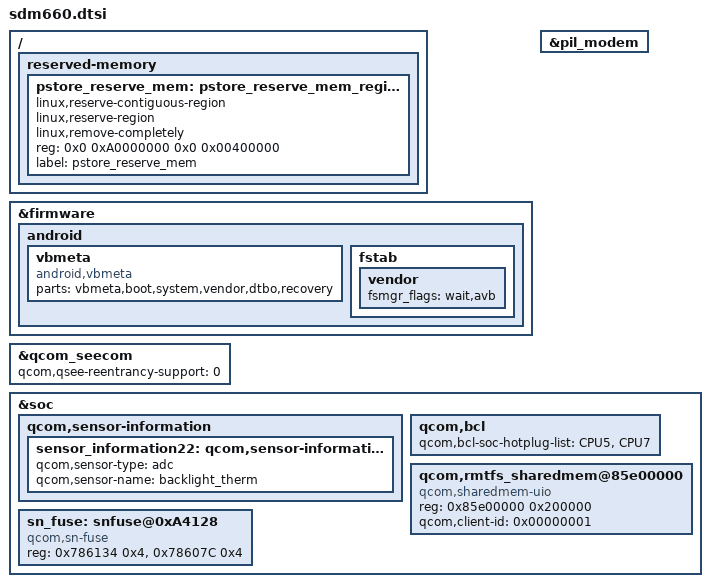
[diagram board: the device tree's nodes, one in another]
/* Copyright (c) 2016-2018, The Linux Foundation. All rights reserved.
 * Copyright (C) 2019 XiaoMi, Inc.
 *
 * This program is free software; you can redistribute it and/or modify
 * it under the terms of the GNU General Public License version 2 and
 * only version 2 as published by the Free Software Foundation.
 *
 * This program is distributed in the hope that it will be useful,
 * but WITHOUT ANY WARRANTY; without even the implied warranty of
 * MERCHANTABILITY or FITNESS FOR A PARTICULAR PURPOSE.  See the
 * GNU General Public License for more details.
 */

&firmware {
	android {
		vbmeta {
			compatible = "android,vbmeta";
			parts = "vbmeta,boot,system,vendor,dtbo,recovery";
		};

		fstab {
			vendor {
				fsmgr_flags = "wait,avb";
			};
		};
	};
};

/ {
	reserved-memory {
		pstore_reserve_mem: pstore_reserve_mem_region@0 {
			linux,reserve-contiguous-region;
			linux,reserve-region;
			linux,remove-completely;
			reg = <0x0 0xA0000000 0x0 0x00400000>;
			label = "pstore_reserve_mem";
		};
	};
};

&pil_modem {
	/delete-property/ qcom,complete-ramdump;
};

&qcom_seecom {
	qcom,qsee-reentrancy-support = <0>;
};

&soc {
	/delete-node/ qcom,qbt1000;

	qcom,sensor-information {
		sensor_information22: qcom,sensor-information-22 {
			qcom,sensor-type = "adc";
			qcom,sensor-name = "backlight_therm";
		};
	};

	qcom,bcl {
		qcom,bcl-soc-hotplug-list = <&CPU5 &CPU7>;
	};

	/delete-node/ qcom,rmtfs_sharedmem@0;
	qcom,rmtfs_sharedmem@85e00000 {
		compatible = "qcom,sharedmem-uio";
		reg = <0x85e00000 0x200000>;
		reg-names = "rmtfs";
		qcom,client-id = <0x00000001>;
	};

	sn_fuse: snfuse@0xA4128 {
		 compatible = "qcom,sn-fuse";
		 reg = <0x786134 0x4>,
			 <0x78607C 0x4>;
		 reg-names = "sn-base","fuse-state";
	 };
};

#include "msm-pm660.dtsi"
#include "msm-pm660l.dtsi"
#include "sdm660-regulator.dtsi"
#include "sdm660-common.dtsi"
#include "sdm660-blsp.dtsi"
#include "sdm660-camera.dtsi"
#include "msm-audio.dtsi"
#include "sdm660-audio.dtsi"

#include "sdm660-mdss-panels.dtsi"
